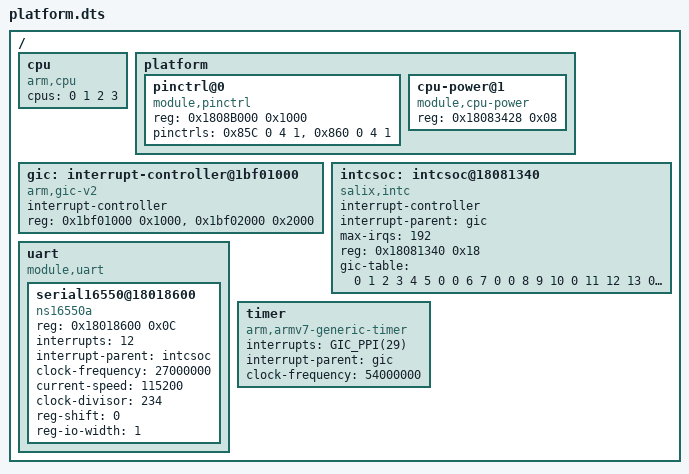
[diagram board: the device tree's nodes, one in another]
/*
 * SPDX-License-Identifier: Apache-2.0
 * Copyright (c) 2019 KapaXL (kapa.xl@outlook.com)
 */

/dts-v1/;

#include "memory.dtsi"

#define GIC_SPI(x) ((x) + 32)
#define GIC_PPI(x) ((x))

/ {
	cpu {
		compatible = "arm,cpu";
		/* mpid of each CPU */
		cpus = <0 1 2 3>;
	};

	platform {
		#address-cells = <1>;
		#size-cells = <1>;

		/*
		 * pinctrls cells information
		 * 0: reg offset,
		 * 1: first bit position,
		 * 2: number of bits,
		 * 3: value
		 */
		pinctrl@0 {
			compatible = "module,pinctrl";
			reg = <0x1808B000 0x1000>;
			pinctrls = <0x85C 0 4 1>, /* uart2 - TX */
				<0x860 0 4 1>; /* uart2 - RX */
		};

		cpu-power@1 {
			compatible = "module,cpu-power";
			reg = <0x18083428 0x08>;
		};
	};

	/* interrupt-controller: CPU side */
	gic: interrupt-controller@1bf01000 {
		compatible = "arm,gic-v2";

		interrupt-controller;

		#interrupt-cells = <1>;

		reg = <0x1bf01000 0x1000>, /* GICD */
			<0x1bf02000 0x2000>; /* GICC */
	};

	/* interrupt-controller: SoC side */
	intcsoc: intcsoc@18081340 {
		compatible = "salix,intc";

		interrupt-controller;

		#interrupt-cells = <1>;

		interrupt-parent = <&gic>;

		max-irqs = <192>;

		reg = <0x18081340 0x18>;

		gic-table = <0 1 2 3 4 5 0 0 6 7 0 0 8 9 10 0
			11 12 13 0 14 92 93 0 17 18 0 0 19 20 0 0
			21 22 23 24 0 0 0 0 25 26 0 0 0 0 0 0
			0 0 0 0 27 28 29 30 31 32 33 34 35 0 0 0
			36 0 0 0 37 38 39 40 41 42 0 0 43 44 45 0
			46 0 0 0 47 48 49 0 0 0 0 0 0 0 0 0
			50 51 52 53 54 55 56 57 58 59 60 61 0 0 0 0
			96 97 98 99 62 63 64 65 66 67 68 0 0 0 0 0
			69 70 71 72 73 74 75 76 77 78 79 80 81 82 83 84
			85 86 87 88 89 89 91 91 0 0 0 0 91 94 0 95
			113 114 115 116 117 118 119 0 0 0 0 0 0 0 0 0
			120 0 0 0 121 0 0 0 122 123 0 0 124 15 16 0>;
	};

	uart {
		compatible = "module,uart";
		#address-cells = <1>;
		#size-cells = <1>;

		serial16550@18018600 {
			compatible = "ns16550a"; /* uart2 */
			reg = <0x18018600 0x0C>;
			interrupts = <12>;
			interrupt-parent = <&intcsoc>;
			clock-frequency = <27000000>;
			current-speed = <115200>;
			clock-divisor = <234>;
			reg-shift = <0>;
			reg-io-width = <1>;
		};
	};

	timer {
		compatible = "arm,armv7-generic-timer";
		interrupts = <GIC_PPI(29)>; /* PPI 29 for SecureWorld tick_timer, 30 for REE */
		interrupt-parent = <&gic>;
		clock-frequency = <54000000>;
	};
};
